# va108xx register map
Vendor: VORAGO TECHNOLOGIES; Series: M0; File version: 1.2-IAR
CPU: CM0 r0p0, little endian, no MPU, no FPU, 2 interrupt priority bits
Registers are 32-bit, read-write, reset 0x0 unless marked. A register's access mark holds for its fields unless they carry their own. Offsets are from the block's base; [hi:lo] are bit positions; {n}, {i} and the like mark numbered series; 'fields as' and 'values as' point back to an identical list.

## IRQSEL — Interrupt Selector Peripheral
Base 0x40001000
{0x0+4i} PORTA[{i}] (i=0..31) reset 0xFFFFFFFF — PORTA Interrupt Redirect Selection
{0x80+4i} PORTB[{i}] (i=0..31) reset 0xFFFFFFFF — PORTB Interrupt Redirect Selection
{0x100+4i} TIM[{i}] (i=0..31) reset 0xFFFFFFFF — TIM Interrupt Redirect Selection
{0x180+4i} UART[{i}] (i=0..3) reset 0xFFFFFFFF — UART Interrupt Redirect Selection
{0x190+4i} SPI[{i}] (i=0..3) reset 0xFFFFFFFF — SPI Interrupt Redirect Selection
{0x1A0+4i} I2C_MS[{i}] (i=0..3) reset 0xFFFFFFFF — Master I2C Interrupt Redirect Selection
{0x1B0+4i} I2C_SL[{i}] (i=0..3) reset 0xFFFFFFFF — Slave I2C Interrupt Redirect Selection
0x1C0 INT_RAM_SBE reset 0xFFFFFFFF — Internal Memory RAM SBE Interrupt Redirect Selection
0x1C4 INT_RAM_MBE reset 0xFFFFFFFF — Internal Memory RAM MBE Interrupt Redirect Selection
0x1C8 INT_ROM_SBE reset 0xFFFFFFFF — Internal Memory ROM SBE Interrupt Redirect Selection
0x1CC INT_ROM_MBE reset 0xFFFFFFFF — Internal Memory ROM MBE Interrupt Redirect Selection
0x1D0 TXEV reset 0xFFFFFFFF — Processor TXEV Interrupt Redirect Selection
{0x800+4i} IRQS[{i}] (i=0..31) ro — Interrupt Status Register
  [0] ACTIVE
0x8E8 EDBGRQ ro — EDBGRQ Status Register
  [0] ACTIVE
0x8EC MERESET ro — MERESET Status Register
  [0] ACTIVE
0x8F0 WATCHDOG ro — WATCHDOG Status Register
  [0] ACTIVE
0x8F4 RXEV ro — RXEV Status Register
  [0] ACTIVE
0x8F8 NMI ro — NMI Status Register
  [0] ACTIVE
0xFFC PERID ro reset 0x8007E1 — Peripheral ID Register

## IOCONFIG — IO Pin Configuration Peripheral
Base 0x40002000
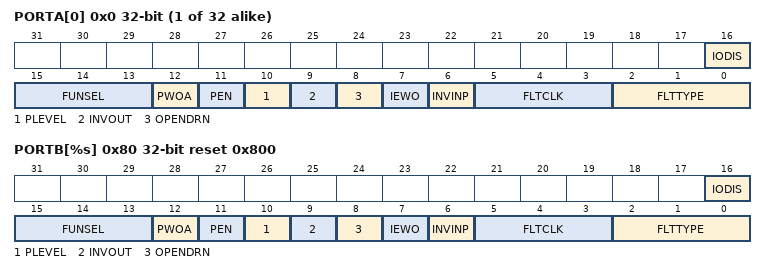
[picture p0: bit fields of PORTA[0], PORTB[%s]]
{0x0+4i} PORTA[{i}] (i=0..31) — PORTA Pin Configuration Register
  [16] IODIS — IO Pin Disable
  [15:13] FUNSEL — Pin Function Selection
  [12] PWOA — Enable Pull when output active
  [11] PEN — Enable Internal Pull up/down
  [10] PLEVEL — Internal Pull up/down level
  [9] INVOUT — Output Invert Selection
  [8] OPENDRN — Output Open Drain Mode
  [7] IEWO — Input Enable While Output enabled
  [6] INVINP — Input Invert Selection
  [5:3] FLTCLK — Input Filter Clock Selection
  [2:0] FLTTYPE — Input Filter Selectoin
    0=SYNC (Synchronize to system clock); 1=DIRECT (Direct input, no synchronization); {v}=FILTER{v-1} (Require {v} samples to have the same value) (v=2..5)
0x80 PORTB[%s] reset 0x800 — PORTB Pin Configuration Register
  fields as PORTA[0]
0xFFC PERID ro reset 0x8207E1 — Peripheral ID Register

## UTILITY — Utility Peripheral
Base 0x40003000
0x00 SYND_DATA0
0x04 SYND_DATA1
0x08 SYND_SYND — Synd Parity Register
0x0C SYND_ENC_32 ro — Synd 32 bit Encoded Syndrome
0x10 SYND_CHECK_32_DATA ro — Synd 32 bit Corrected Data
0x14 SYND_CHECK_32_SYND ro — Synd 32 bit Corrected Syndrome and Status
0x18 SYND_ENC_64 ro — Synd 64 bit Encoded Syndrome
0x1C SYND_CHECK_64_DATA0 ro — Synd 64 bit Corrected Data 0
0x20 SYND_CHECK_64_DATA1 ro — Synd 64 bit Corrected Data 1
0x24 SYND_CHECK_64_SYND ro — Synd 64 bit Corrected Parity and Status
0x28 SYND_ENC_32_52 ro — Synd 32/52 bit Encoded Syndrome
0x2C SYND_CHECK_32_52_DATA ro — Synd 32/52 bit Corrected Data
0x30 SYND_CHECK_32_52_SYND ro — Synd 32/52 bit Corrected Syndrome and Status
0xFFC PERID ro reset 0x8207E1 — Peripheral ID Register

## PORTA — GPIO Peripheral
Base 0x50000000
Same registers: PORTB 0x50001000
0x00 DATAIN ro
{0x0+i} DATAINBYTE[{i}] (i=0..3) 8-bit ro (alternate view of DATAIN) — Data In Register by Byte
0x04 DATAINRAW ro
0x04 DATAINRAWBYTE[%s] 8-bit ro (alternate view of DATAINRAW) — Data In Raw Register by Byte
0x08 DATAOUT wo
{0x8+i} DATAOUTBYTE[{i}] (i=0..3) 8-bit wo (alternate view of DATAOUT) — Data Out Register by Byte
0x0C DATAOUTRAW wo — Data Out Register
0x0C DATAOUTRAWBYTE[%s] 8-bit wo (alternate view of DATAOUTRAW) — Data Out Register by Byte
0x10 SETOUT wo
0x10 SETOUTBYTE[%s] 8-bit wo (alternate view of SETOUT) — Set Out Register by Byte
0x14 CLROUT wo — Clear Out Register
0x14 CLROUTBYTE[%s] 8-bit wo (alternate view of CLROUT) — Clear Out Register by Byte
0x18 TOGOUT wo — Toggle Out Register
0x18 TOGOUTBYTE[%s] 8-bit wo (alternate view of TOGOUT) — Toggle Out Register by Byte
0x1C DATAMASK
{0x1C+i} DATAMASKBYTE[{i}] (i=0..3) 8-bit (alternate view of DATAMASK) — Data Out Register by Byte
0x20 DIR — Direction Register (1:Output, 0:Input)
0x20 DIRBYTE[%s] 8-bit (alternate view of DIR) — Direction Register by Byte
0x24 PULSE — Pulse Mode Register
0x24 PULSEBYTE[%s] 8-bit (alternate view of PULSE) — Pulse Mode Register by Byte
0x28 PULSEBASE — Pulse Base Value Register
0x28 PULSEBASEBYTE[%s] 8-bit (alternate view of PULSEBASE) — Pulse Base Mode Register by Byte
0x2C DELAY1
0x2C DELAY1BYTE[%s] 8-bit (alternate view of DELAY1) — Delay1 Register by Byte
0x30 DELAY2
0x30 DELAY2BYTE[%s] 8-bit (alternate view of DELAY2) — Delay2 Register by Byte
0x34 IRQ_SEN — Interrupt Sense Register (1:Level Sensitive, 0:Edge Sensitive)
0x38 IRQ_EDGE — Interrupt Both Edge Register (1:Both Edges, 0:Single Edge)
0x3C IRQ_EVT — Interrupt Event Register (1:HighLevel/L->H Edge, 0:LowLevel/H->L Edge)
0x40 IRQ_ENB — Interrupt Enable Register
0x44 IRQ_RAW ro — Raw Interrupt Status
0x48 IRQ_END ro — Masked Interrupt Status
0x4C EDGE_STATUS
0xFFC PERID ro reset 0x1007E1 — Peripheral ID Register
